# FM33LG0XX register map
File version: 1.0
CPU: SC123 r1p0, little endian, no MPU, no FPU, 3 interrupt priority bits
Registers are 32-bit, read-write, reset 0x0 unless marked. A register's access mark holds for its fields unless they carry their own. Offsets are from the block's base; [hi:lo] are bit positions; {n}, {i} and the like mark numbered series.

## LCD — LCD module information
Base 0x40010C00
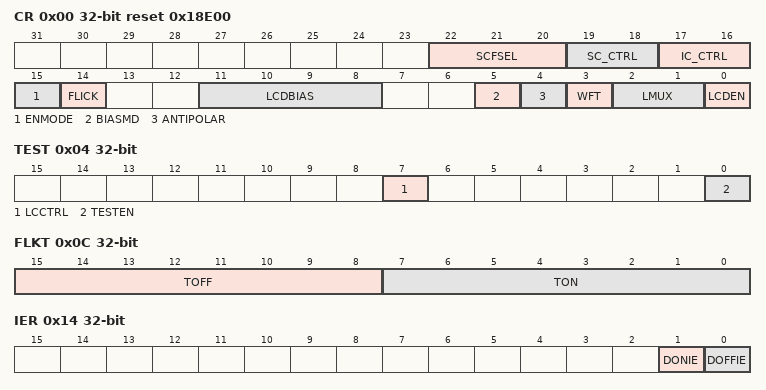
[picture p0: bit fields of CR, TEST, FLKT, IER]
0x00 CR reset 0x18E00 — LCD Control Register
  [22:20] SCFSEL — SCFSEL field description
  [19:18] SC_CTRL — SC_CTRL field description
  [17:16] IC_CTRL — IC_CTRL field description
  [15] ENMODE — ENMODE field description
  [14] FLICK — FLICK field description
  [11:8] LCDBIAS — LCDBIAS field description
  [5] BIASMD — BIASMD field description
  [4] ANTIPOLAR — ANTIPOLAR field description
  [3] WFT — WFT field description
  [2:1] LMUX — LMUX field description
  [0] LCDEN — LCDEN field description
0x04 TEST — LCD test Register
  [7] LCCTRL — LCCTRL field description
  [0] TESTEN — TESTEN field description
0x08 FCR — LCD Frequency Control Register
  [7:0] DF — DF field description
0x0C FLKT — LCD Flick Time Register
  [15:8] TOFF — TOFF field description
  [7:0] TON — TON field description
0x14 IER — LCD Interrupt Enable Register
  [1] DONIE — DONIE field description
  [0] DOFFIE — DOFFIE field description
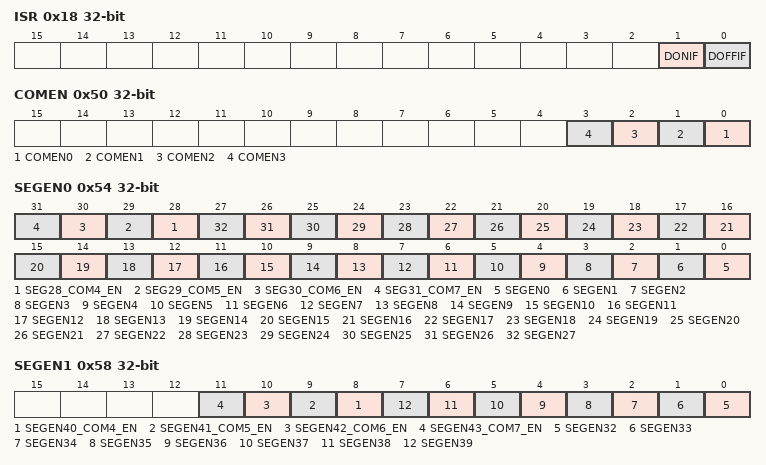
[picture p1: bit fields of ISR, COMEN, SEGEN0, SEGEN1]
0x18 ISR — LCD Interrupt Status Register
  [1] DONIF — DONIF field description
  [0] DOFFIF — DOFFIF field description
{0x24+4i} DATA{i} (i=0..9) — LCD data buffer registers {i}
  [31:0] DSDA — DSDA field description
0x50 COMEN — LCD COM Enable Register
  [n] COMEN{n} (n=0..3) — COMEN{n} field description
0x54 SEGEN0 — LCD SEG Enable Register0
  [n] SEG{n}_COM{n-24}_EN (n=28..31) — SEG{n}_COM{n-24}_EN field description
  [n] SEGEN{n} (n=0..27) — SEGEN{n} field description
0x58 SEGEN1 — LCD SEG Enable Register 1
  [n-32] SEGEN{n}_COM{n-36}_EN (n=40..43) — SEGEN{n}_COM{n-36}_EN field description
  [n-32] SEGEN{n} (n=32..39) — SEGEN{n} field description

## ADC — ADC module information
Base 0x40015C00
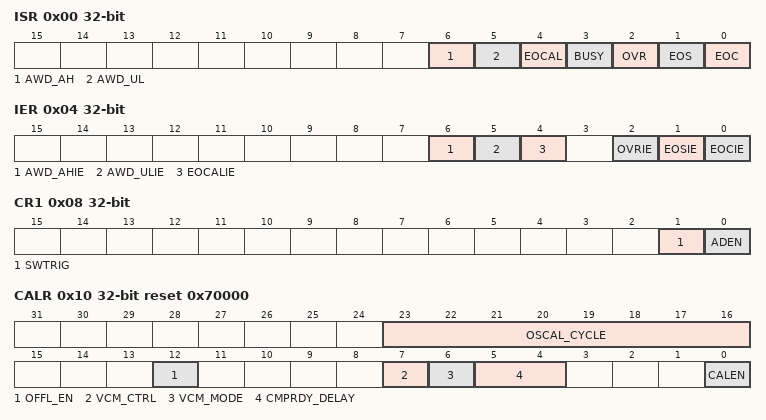
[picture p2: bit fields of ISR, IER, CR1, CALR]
0x00 ISR access per field — ADC Interrupt and Status Register
  [6] AWD_AH rw — AWD_AH field description
  [5] AWD_UL rw — AWD_UL field description
  [4] EOCAL rw — EOCAL field description
  [3] BUSY ro — BUSY field description
  [2] OVR rw — OVR field description
  [1] EOS rw — EOS field description
  [0] EOC rw — EOC field description
0x04 IER — ADC Interrupt Enable Register
  [6] AWD_AHIE — AWD_AHIE field description
  [5] AWD_ULIE — AWD_ULIE field description
  [4] EOCALIE — EOCALIE field description
  [2] OVRIE — OVRIE field description
  [1] EOSIE — EOSIE field description
  [0] EOCIE — EOCIE field description
0x08 CR1 — ADC Control Register
  [1] SWTRIG — SWTRIG field description
  [0] ADEN — ADEN field description
0x0C CR2 — ADC Control Register
  [1:0] TRGCFG — TRGCFG field description
0x10 CALR reset 0x70000 — ADC Calibration Register
  [23:16] OSCAL_CYCLE — OSCAL_CYCLE field description
  [12] OFFL_EN — OFFL_EN field description
  [7] VCM_CTRL — VCM_CTRL field description
  [6] VCM_MODE — VCM_MODE field description
  [5:4] CMPRDY_DELAY — CMPRDY_DELAY field description
  [0] CALEN — CALEN field description
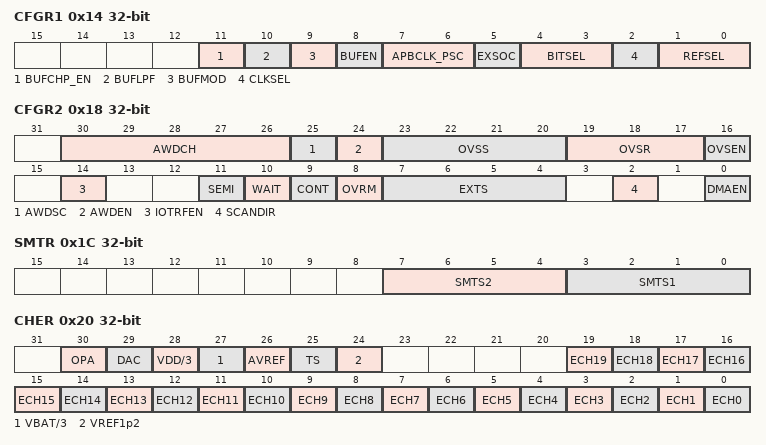
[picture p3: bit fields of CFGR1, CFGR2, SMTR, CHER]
0x14 CFGR1 — ADC Config Register1
  [11] BUFCHP_EN — BUFCHP_EN field description
  [10] BUFLPF — BUFLPF field description
  [9] BUFMOD — BUFMOD field description
  [8] BUFEN — BUFEN field description
  [7:6] APBCLK_PSC — APBCLK_PSC field description
  [5] EXSOC — EXSOC field description
  [4:3] BITSEL — BITSEL field description
  [2] CLKSEL — CLKSEL field description
  [1:0] REFSEL — REFSEL field description
0x18 CFGR2 — ADC Config Register2
  [30:26] AWDCH — AWDCH field description
  [25] AWDSC — AWDSC field description
  [24] AWDEN — AWDEN field description
  [23:20] OVSS — OVSS field description
  [19:17] OVSR — OVSR field description
  [16] OVSEN — OVSEN field description
  [14] IOTRFEN — IOTRFEN field description
  [11] SEMI — SEMI field description
  [10] WAIT — WAIT field description
  [9] CONT — CONT field description
  [8] OVRM — OVRM field description
  [7:4] EXTS — EXTS field description
  [2] SCANDIR — SCANDIR field description
  [0] DMAEN — DMAEN field description
0x1C SMTR — ADC Sampling Time Register
  [7:4] SMTS2 — SMTS2 field description
  [3:0] SMTS1 — SMTS1 field description
0x20 CHER — ADC Channel Enable Register
  [30] OPA — OPA field description
  [29] DAC — DAC field description
  [28] VDD/3 — VDD/3 field description
  [27] VBAT/3 — VBAT/3 field description
  [26] AVREF — AVREF field description
  [25] TS — TS field description
  [24] VREF1p2 — VREF1p2 field description
  [n] ECH{n} (n=0..19) — ECH{n} field description
0x24 DCR — ADC Differential Channel Control Register
  [6:0] AINS — AINS field description
0x28 DR ro — ADC Data Register
  [15:0] DATA — DATA field description
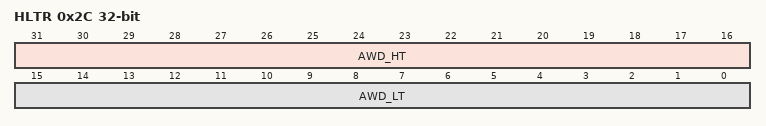
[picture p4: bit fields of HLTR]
0x2C HLTR — ADC analog watchdog Threshold Register
  [31:16] AWD_HT — AWD_HT field description
  [15:0] AWD_LT — AWD_LT field description
